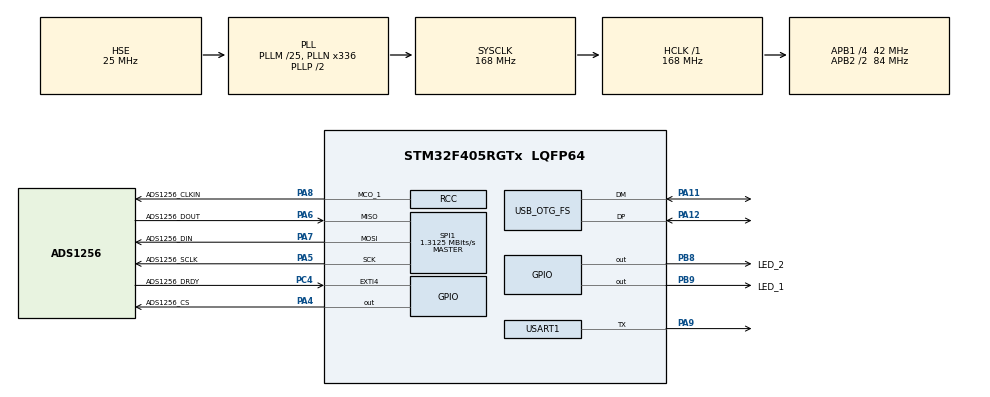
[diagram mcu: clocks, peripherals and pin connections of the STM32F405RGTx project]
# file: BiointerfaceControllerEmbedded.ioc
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Mcu.Family=STM32F4
Mcu.Name=STM32F405RGTx
Mcu.Package=LQFP64
NVIC.EXTI4_IRQn=true\:1\:0\:true\:false\:true\:true\:true
NVIC.OTG_FS_IRQn=true\:0\:0\:true\:false\:true\:false\:true
NVIC.PriorityGroup=NVIC_PRIORITYGROUP_4
NVIC.TIM2_IRQn=true\:2\:0\:true\:false\:true\:true\:true
PA11.Mode=Device_Only
PA11.Signal=USB_OTG_FS_DM
PA12.Mode=Device_Only
PA12.Signal=USB_OTG_FS_DP
PA13.Mode=Serial_Wire
PA13.Signal=SYS_JTMS-SWDIO
PA14.Mode=Serial_Wire
PA14.Signal=SYS_JTCK-SWCLK
PA4.GPIO_Label=ADS1256_CS
PA4.GPIO_PuPd=GPIO_PULLUP
PA4.GPIO_Speed=GPIO_SPEED_FREQ_MEDIUM
PA4.PinState=GPIO_PIN_SET
PA4.Signal=GPIO_Output
PA5.GPIO_Label=ADS1256_SCLK
PA5.GPIO_PuPd=GPIO_PULLDOWN
PA5.Mode=Full_Duplex_Master
PA5.Signal=SPI1_SCK
PA6.GPIO_Label=ADS1256_DOUT
PA6.GPIO_PuPd=GPIO_PULLDOWN
PA6.Mode=Full_Duplex_Master
PA6.Signal=SPI1_MISO
PA7.GPIO_Label=ADS1256_DIN
PA7.GPIO_PuPd=GPIO_NOPULL
PA7.Mode=Full_Duplex_Master
PA7.Signal=SPI1_MOSI
PA8.GPIO_Label=ADS1256_CLKIN
PA8.GPIO_PuPd=GPIO_PULLDOWN
PA8.Mode=Clock-out-1
PA8.Signal=RCC_MCO_1
PA9.GPIO_PuPd=GPIO_PULLUP
PA9.Mode=Half_duplex(single_wire_mode)
PA9.Signal=USART1_TX
PB8.GPIO_Label=LED_2
PB8.GPIO_PuPd=GPIO_PULLDOWN
PB8.Signal=GPIO_Output
PB9.GPIO_Label=LED_1
PB9.GPIO_PuPd=GPIO_PULLDOWN
PB9.Signal=GPIO_Output
PC4.GPIO_Label=ADS1256_DRDY
PC4.GPIO_ModeDefaultEXTI=GPIO_MODE_IT_FALLING
PC4.GPIO_PuPd=GPIO_NOPULL
PC4.Signal=GPXTI4
PH0-OSC_IN.Mode=HSE-External-Oscillator
PH0-OSC_IN.Signal=RCC_OSC_IN
PH1-OSC_OUT.Mode=HSE-External-Oscillator
PH1-OSC_OUT.Signal=RCC_OSC_OUT
ProjectManager.HeapSize=0x4000
ProjectManager.StackSize=0x8000
ProjectManager.TargetToolchain=MDK-ARM V5.27
RCC.48MHZClocksFreq_Value=48000000
RCC.AHBFreq_Value=168000000
RCC.APB1CLKDivider=RCC_HCLK_DIV4
RCC.APB1Freq_Value=42000000
RCC.APB1TimFreq_Value=84000000
RCC.APB2CLKDivider=RCC_HCLK_DIV2
RCC.APB2Freq_Value=84000000
RCC.APB2TimFreq_Value=168000000
RCC.CortexFreq_Value=168000000
RCC.EnbaleCSS=true
RCC.HCLKFreq_Value=168000000
RCC.HSE_Timout=100
RCC.HSE_VALUE=25000000
RCC.HSICalibrationValue=10
RCC.HSI_VALUE=16000000
RCC.LSE_VALUE=32768
RCC.PLLM=25
RCC.PLLN=336
RCC.PLLQ=7
RCC.RCC_MCODiv1=RCC_MCODIV_2
RCC.SYSCLKFreq_VALUE=168000000
RCC.SYSCLKSource=RCC_SYSCLKSOURCE_PLLCLK
RCC.VCOOutputFreq_Value=336000000
SPI1.BaudRatePrescaler=SPI_BAUDRATEPRESCALER_64
SPI1.CLKPhase=SPI_PHASE_2EDGE
SPI1.CalculateBaudRate=1.3125 MBits/s
SPI1.Direction=SPI_DIRECTION_2LINES
SPI1.Mode=SPI_MODE_MASTER
SPI1.VirtualType=VM_MASTER
TIM2.Period=2624
TIM2.Prescaler=15
TIM2.TIM_MasterOutputTrigger=TIM_TRGO_UPDATE
USART1.BaudRate=256000
USART1.Mode=MODE_TX
USART1.VirtualMode=VM_ASYNC
USB_DEVICE.APP_RX_DATA_SIZE-CDC_FS=512
USB_DEVICE.APP_TX_DATA_SIZE-CDC_FS=2048
USB_DEVICE.CLASS_NAME_FS=CDC
USB_DEVICE.MANUFACTURER_STRING-CDC_FS=itgavrilov@gmail.com
USB_DEVICE.PRODUCT_STRING_CDC_FS=BiointerfaceController
USB_DEVICE.USBD_MAX_STR_DESC_SIZ-CDC_FS=128
USB_DEVICE.VirtualMode-CDC_FS=Cdc
USB_DEVICE.VirtualModeFS=Cdc_FS
USB_OTG_FS.VirtualMode=Device_Only
VP_TIM2_VS_ClockSourceINT.Mode=Internal
VP_USB_DEVICE_VS_USB_DEVICE_CDC_FS.Mode=CDC_FS
board=custom

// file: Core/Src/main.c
/* USER CODE BEGIN Header */
/**
  ******************************************************************************
  * @file           : main.c
  * @brief          : Main program body
  ******************************************************************************
  * @attention
  *
  * <h2><center>&copy; Copyright (c) 2021 STMicroelectronics.
  * All rights reserved.</center></h2>
  *
  * This software component is licensed by ST under Ultimate Liberty license
  * SLA0044, the "License"; You may not use this file except in compliance with
  * the License. You may obtain a copy of the License at:
  *                             www.st.com/SLA0044
  *
  ******************************************************************************
  */
/* USER CODE END Header */
#include "main.h"
#include "spi.h"
#include "tim.h"
#include "usart.h"
#include "usb_device.h"
#include "gpio.h"

/* USER CODE BEGIN Includes */
#include "biointerfaceControllerLib.h"
/* USER CODE END Includes */

void SystemClock_Config(void);

/* USER CODE BEGIN 0 */
#ifdef USE_FULL_ASSERT
/**
  * @brief  Retargets the C library printf function to the USART.
  * @param  None
  * @retval None
  */
PUTCHAR_PROTOTYPE
{
  /* Place your implementation of fputc here */
  /* e.g. write a character to the EVAL_COM1 and Loop until the end of transmission */
	HAL_UART_Transmit(&huart1, (void*)&ch, 1, 1000);

  //HAL_UART_Transmit(&UartHandle, (uint8_t *)&ch, 1, 0xFFFF);

  return ch;
}
#endif /* USE_FULL_ASSERT */
/* USER CODE END 0 */

int main(void)
{

  /* MCU Configuration--------------------------------------------------------*/

  /* Reset of all peripherals, Initializes the Flash interface and the Systick. */
  HAL_Init();

  /* Configure the system clock */
  SystemClock_Config();

  /* Initialize all configured peripherals */
  MX_GPIO_Init();
  MX_TIM2_Init();
  MX_USB_DEVICE_Init();
  MX_SPI1_Init();
  MX_USART1_UART_Init();
  /* USER CODE BEGIN 2 */
	initController();
  /* USER CODE END 2 */

  /* Infinite loop */
  while (1)
  {

  }
}

void SystemClock_Config(void)
{
  RCC_OscInitTypeDef RCC_OscInitStruct = {0};
  RCC_ClkInitTypeDef RCC_ClkInitStruct = {0};

  /** Configure the main internal regulator output voltage
  */
  __HAL_RCC_PWR_CLK_ENABLE();
  __HAL_PWR_VOLTAGESCALING_CONFIG(PWR_REGULATOR_VOLTAGE_SCALE1);
  /** Initializes the RCC Oscillators according to the specified parameters
  * in the RCC_OscInitTypeDef structure.
  */
  RCC_OscInitStruct.OscillatorType = RCC_OSCILLATORTYPE_HSI|RCC_OSCILLATORTYPE_HSE;
  RCC_OscInitStruct.HSEState = RCC_HSE_ON;
  RCC_OscInitStruct.HSIState = RCC_HSI_ON;
  RCC_OscInitStruct.HSICalibrationValue = 10;
  RCC_OscInitStruct.PLL.PLLState = RCC_PLL_ON;
  RCC_OscInitStruct.PLL.PLLSource = RCC_PLLSOURCE_HSE;
  RCC_OscInitStruct.PLL.PLLM = 25;
  RCC_OscInitStruct.PLL.PLLN = 336;
  RCC_OscInitStruct.PLL.PLLP = RCC_PLLP_DIV2;
  RCC_OscInitStruct.PLL.PLLQ = 7;
  if (HAL_RCC_OscConfig(&RCC_OscInitStruct) != HAL_OK)
  {
    Error_Handler();
  }
  /** Initializes the CPU, AHB and APB buses clocks
  */
  RCC_ClkInitStruct.ClockType = RCC_CLOCKTYPE_HCLK|RCC_CLOCKTYPE_SYSCLK
                              |RCC_CLOCKTYPE_PCLK1|RCC_CLOCKTYPE_PCLK2;
  RCC_ClkInitStruct.SYSCLKSource = RCC_SYSCLKSOURCE_PLLCLK;
  RCC_ClkInitStruct.AHBCLKDivider = RCC_SYSCLK_DIV1;
  RCC_ClkInitStruct.APB1CLKDivider = RCC_HCLK_DIV4;
  RCC_ClkInitStruct.APB2CLKDivider = RCC_HCLK_DIV2;

  if (HAL_RCC_ClockConfig(&RCC_ClkInitStruct, FLASH_LATENCY_5) != HAL_OK)
  {
    Error_Handler();
  }
  HAL_RCC_MCOConfig(RCC_MCO1, RCC_MCO1SOURCE_HSI, RCC_MCODIV_2);
  /** Enables the Clock Security System
  */
  HAL_RCC_EnableCSS();
}

void Error_Handler(void)
{
  __disable_irq();
  while (1)
  {
  }
}

/************************ (C) COPYRIGHT STMicroelectronics *****END OF FILE****/
